VERSION ""

NS_ :

BS_:

BU_: DDU7

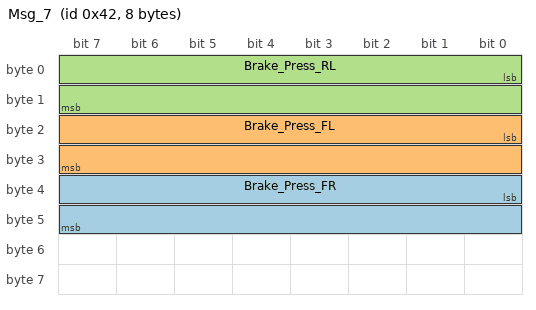
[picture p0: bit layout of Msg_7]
BO_ 66 Msg_7: 8 DDU7
 SG_ Brake_Press_FR : 32|16@1- (0.1,0) [-3276.8|3276.7] "psi" Vector__XXX
 SG_ Brake_Press_FL : 16|16@1- (0.1,0) [-3276.8|3276.7] "psi" Vector__XXX
 SG_ Brake_Press_RL : 0|16@1- (0.1,0) [-3276.8|3276.7] "psi" Vector__XXX

BO_ 50 Msg_2: 8 DDU7
 SG_ Brake_Press_RR : 0|16@1- (0.1,0) [-3276.8|3276.7] "psi" Vector__XXX
